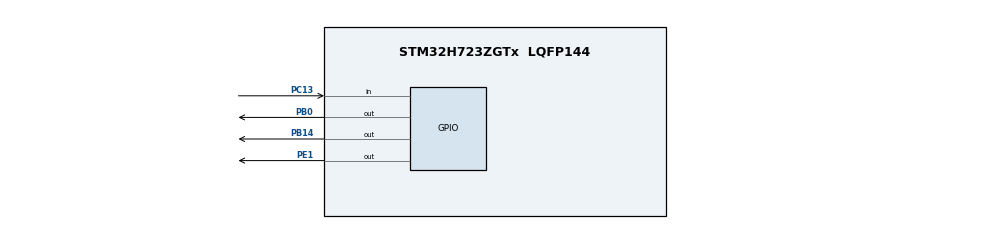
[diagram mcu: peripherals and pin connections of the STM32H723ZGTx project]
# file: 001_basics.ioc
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CORTEX_M7.default_mode_Activation=1
Mcu.Family=STM32H7
Mcu.Name=STM32H723ZGTx
Mcu.Package=LQFP144
NUCLEO-H723ZG.BUTTON=1
NUCLEO-H723ZG.LD1=true
NUCLEO-H723ZG.LD2=true
NUCLEO-H723ZG.LD3=true
NUCLEO-H723ZG.VCP=true
NVIC.EXTI15_10_IRQn=true\:0\:0\:false\:false\:true\:false\:true\:true
NVIC.PriorityGroup=NVIC_PRIORITYGROUP_4
PA13(JTMS/SWDIO).GPIO_Label=SWDIO
PA13(JTMS/SWDIO).Signal=DEBUG_JTMS-SWDIO
PA14(JTCK/SWCLK).GPIO_Label=SWCLK
PA14(JTCK/SWCLK).Signal=DEBUG_JTCK-SWCLK
PB0.Signal=GPIO_Output
PB14.Signal=GPIO_Output
PC13.Signal=GPIO_Input
PC14-OSC32_IN.Signal=RCC_OSC32_IN
PC15-OSC32_OUT.Signal=RCC_OSC32_OUT
PD8.Signal=USART3_TX
PD9.Signal=USART3_RX
PE1.Signal=GPIO_Output
PH0-OSC_IN.Mode=HSE-External-Oscillator
PH0-OSC_IN.Signal=RCC_OSC_IN
PH1-OSC_OUT.Mode=HSE-External-Oscillator
PH1-OSC_OUT.Signal=RCC_OSC_OUT
ProjectManager.HeapSize=0x200
ProjectManager.StackSize=0x400
ProjectManager.TargetToolchain=STM32CubeIDE
RCC.ADCFreq_Value=76000000
RCC.APB1Freq_Value=137500000
RCC.APB2Freq_Value=137500000
RCC.APB3Freq_Value=137500000
RCC.APB4Freq_Value=137500000
RCC.CortexFreq_Value=275000000
RCC.D1PPRE=RCC_APB3_DIV2
RCC.D2PPRE1=RCC_APB1_DIV2
RCC.D2PPRE2=RCC_APB2_DIV2
RCC.D3PPRE=RCC_APB4_DIV2
RCC.DIVM1=1
RCC.DIVM2=1
RCC.DIVN1=34
RCC.DIVN2=19
RCC.DIVP1=1
RCC.DIVQ1=4
RCC.HCLKFreq_Value=275000000
RCC.HSE_VALUE=8000000
RCC.PLLFRACN=3072
RCC.PLLSourceVirtual=RCC_PLLSOURCE_HSE
RCC.SYSCLKFreq_VALUE=275000000
RCC.SYSCLKSource=RCC_SYSCLKSOURCE_PLLCLK
RCC.USBCLockSelection=RCC_USBCLKSOURCE_HSI48
RCC.USBFreq_Value=48000000
VP_MEMORYMAP_VS_MEMORYMAP.Mode=CurAppReg
VP_NUCLEO-H723ZG_VS_BSP_COMMON.Mode=COMMON
board=NUCLEO-H723ZG

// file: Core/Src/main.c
/* USER CODE BEGIN Header */
/**
  ******************************************************************************
  * @file           : main.c
  * @brief          : Main program body
  ******************************************************************************
  * @attention
  *
  * Copyright (c) 2025 STMicroelectronics.
  * All rights reserved.
  *
  * This software is licensed under terms that can be found in the LICENSE file
  * in the root directory of this software component.
  * If no LICENSE file comes with this software, it is provided AS-IS.
  *
  ******************************************************************************
  */
/* USER CODE END Header */
#include "main.h"

COM_InitTypeDef BspCOMInit;

void SystemClock_Config(void);
static void MPU_Config(void);
static void MX_GPIO_Init(void);

/* USER CODE BEGIN 0 */

int32_t result = 0;
int32_t result_op = 0;
int32_t x = 5, n = 10;

int32_t f(int32_t x, int32_t n) {

	int32_t tempResult = 0;
	for (uint32_t i = 1; i <= n; ++i) {
		tempResult += x * i + i * i;
	}
	return tempResult;
}

int32_t f_op(int32_t x, int32_t n) {

	return x*(n*(n+1)/2) + (n*(n+1)*(2*n+1)/6);
}

/* USER CODE END 0 */

int main(void)
{

  /* MPU Configuration--------------------------------------------------------*/
  MPU_Config();

  /* MCU Configuration--------------------------------------------------------*/

  /* Reset of all peripherals, Initializes the Flash interface and the Systick. */
  HAL_Init();

  /* Configure the system clock */
  SystemClock_Config();

  /* Initialize all configured peripherals */
  MX_GPIO_Init();

  /* Initialize leds */
  BSP_LED_Init(LED_GREEN);
  BSP_LED_Init(LED_YELLOW);
  BSP_LED_Init(LED_RED);

  /* Initialize USER push-button, will be used to trigger an interrupt each time it's pressed.*/
  BSP_PB_Init(BUTTON_USER, BUTTON_MODE_EXTI);

  /* Initialize COM1 port (115200, 8 bits (7-bit data + 1 stop bit), no parity */
  BspCOMInit.BaudRate   = 115200;
  BspCOMInit.WordLength = COM_WORDLENGTH_8B;
  BspCOMInit.StopBits   = COM_STOPBITS_1;
  BspCOMInit.Parity     = COM_PARITY_NONE;
  BspCOMInit.HwFlowCtl  = COM_HWCONTROL_NONE;
  if (BSP_COM_Init(COM1, &BspCOMInit) != BSP_ERROR_NONE)
  {
    Error_Handler();
  }

  /* Infinite loop */
  while (1)
  {

    /* USER CODE BEGIN 3 */
	  result = f(x, n);
	  result_op = f_op(x, n);

  }
  /* USER CODE END 3 */
}

void SystemClock_Config(void)
{
  RCC_OscInitTypeDef RCC_OscInitStruct = {0};
  RCC_ClkInitTypeDef RCC_ClkInitStruct = {0};

  /** Supply configuration update enable
  */
  HAL_PWREx_ConfigSupply(PWR_LDO_SUPPLY);

  /** Configure the main internal regulator output voltage
  */
  __HAL_PWR_VOLTAGESCALING_CONFIG(PWR_REGULATOR_VOLTAGE_SCALE0);

  while(!__HAL_PWR_GET_FLAG(PWR_FLAG_VOSRDY)) {}

  /** Initializes the RCC Oscillators according to the specified parameters
  * in the RCC_OscInitTypeDef structure.
  */
  RCC_OscInitStruct.OscillatorType = RCC_OSCILLATORTYPE_HSE;
  RCC_OscInitStruct.HSEState = RCC_HSE_ON;
  RCC_OscInitStruct.PLL.PLLState = RCC_PLL_ON;
  RCC_OscInitStruct.PLL.PLLSource = RCC_PLLSOURCE_HSE;
  RCC_OscInitStruct.PLL.PLLM = 1;
  RCC_OscInitStruct.PLL.PLLN = 34;
  RCC_OscInitStruct.PLL.PLLP = 1;
  RCC_OscInitStruct.PLL.PLLQ = 4;
  RCC_OscInitStruct.PLL.PLLR = 2;
  RCC_OscInitStruct.PLL.PLLRGE = RCC_PLL1VCIRANGE_3;
  RCC_OscInitStruct.PLL.PLLVCOSEL = RCC_PLL1VCOWIDE;
  RCC_OscInitStruct.PLL.PLLFRACN = 3072;
  if (HAL_RCC_OscConfig(&RCC_OscInitStruct) != HAL_OK)
  {
    Error_Handler();
  }

  /** Initializes the CPU, AHB and APB buses clocks
  */
  RCC_ClkInitStruct.ClockType = RCC_CLOCKTYPE_HCLK|RCC_CLOCKTYPE_SYSCLK
                              |RCC_CLOCKTYPE_PCLK1|RCC_CLOCKTYPE_PCLK2
                              |RCC_CLOCKTYPE_D3PCLK1|RCC_CLOCKTYPE_D1PCLK1;
  RCC_ClkInitStruct.SYSCLKSource = RCC_SYSCLKSOURCE_PLLCLK;
  RCC_ClkInitStruct.SYSCLKDivider = RCC_SYSCLK_DIV1;
  RCC_ClkInitStruct.AHBCLKDivider = RCC_HCLK_DIV1;
  RCC_ClkInitStruct.APB3CLKDivider = RCC_APB3_DIV2;
  RCC_ClkInitStruct.APB1CLKDivider = RCC_APB1_DIV2;
  RCC_ClkInitStruct.APB2CLKDivider = RCC_APB2_DIV2;
  RCC_ClkInitStruct.APB4CLKDivider = RCC_APB4_DIV2;

  if (HAL_RCC_ClockConfig(&RCC_ClkInitStruct, FLASH_LATENCY_3) != HAL_OK)
  {
    Error_Handler();
  }
}

static void MX_GPIO_Init(void)
{

  /* GPIO Ports Clock Enable */
  __HAL_RCC_GPIOC_CLK_ENABLE();
  __HAL_RCC_GPIOH_CLK_ENABLE();
  __HAL_RCC_GPIOA_CLK_ENABLE();

}

 /* MPU Configuration */

void MPU_Config(void)
{
  MPU_Region_InitTypeDef MPU_InitStruct = {0};

  /* Disables the MPU */
  HAL_MPU_Disable();

  /** Initializes and configures the Region and the memory to be protected
  */
  MPU_InitStruct.Enable = MPU_REGION_ENABLE;
  MPU_InitStruct.Number = MPU_REGION_NUMBER0;
  MPU_InitStruct.BaseAddress = 0x0;
  MPU_InitStruct.Size = MPU_REGION_SIZE_4GB;
  MPU_InitStruct.SubRegionDisable = 0x87;
  MPU_InitStruct.TypeExtField = MPU_TEX_LEVEL0;
  MPU_InitStruct.AccessPermission = MPU_REGION_NO_ACCESS;
  MPU_InitStruct.DisableExec = MPU_INSTRUCTION_ACCESS_DISABLE;
  MPU_InitStruct.IsShareable = MPU_ACCESS_SHAREABLE;
  MPU_InitStruct.IsCacheable = MPU_ACCESS_NOT_CACHEABLE;
  MPU_InitStruct.IsBufferable = MPU_ACCESS_NOT_BUFFERABLE;

  HAL_MPU_ConfigRegion(&MPU_InitStruct);
  /* Enables the MPU */
  HAL_MPU_Enable(MPU_PRIVILEGED_DEFAULT);

}

void Error_Handler(void)
{
  __disable_irq();
  while (1)
  {
  }
}
